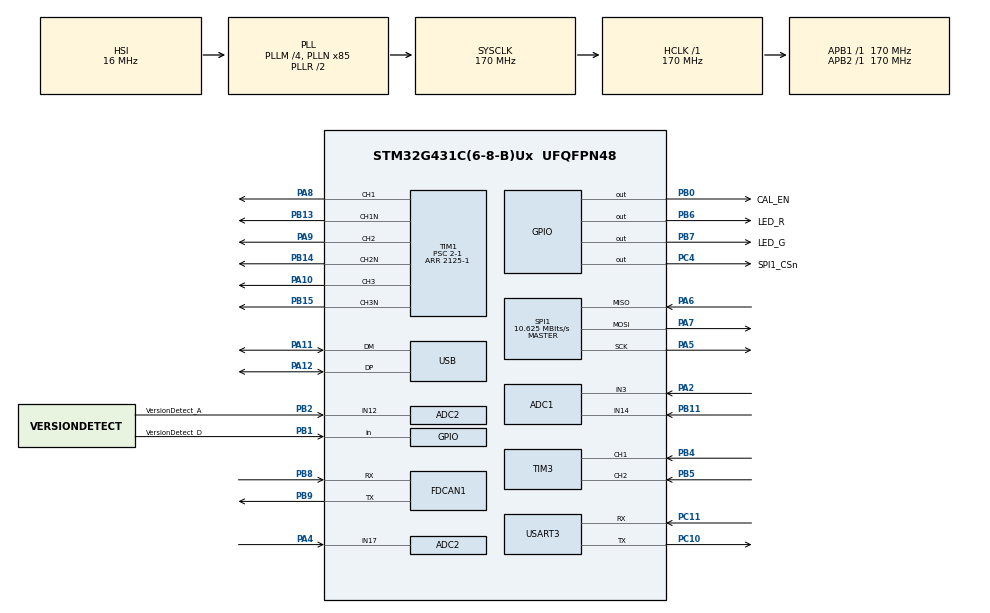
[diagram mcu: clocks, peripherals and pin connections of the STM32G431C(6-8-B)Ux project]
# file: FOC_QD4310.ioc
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ADC1.Channel-2\#ChannelRegularConversion=ADC_CHANNEL_14
ADC1.ClockPrescaler=ADC_CLOCK_SYNC_PCLK_DIV4
ADC1.ContinuousConvMode=DISABLE
ADC1.DMAAccessModeView=DISABLED
ADC1.DMAContinuousRequests=DISABLE
ADC1.EnableAnalogWatchDog1=false
ADC1.EnableInjectedConversion=ENABLE
ADC1.EnableRegularConversion=ENABLE
ADC1.ExternalTrigInjecConv=ADC_EXTERNALTRIGINJEC_T1_TRGO2
ADC1.InjNumberOfConversion=1
ADC1.InjectedChannel-1\#ChannelInjectedConversion=ADC_CHANNEL_3
ADC1.InjectedOffsetNumber-1\#ChannelInjectedConversion=ADC_OFFSET_NONE
ADC1.InjectedRank-1\#ChannelInjectedConversion=1
ADC1.InjectedSamplingTime-1\#ChannelInjectedConversion=ADC_SAMPLETIME_2CYCLES_5
ADC1.Mode=ADC_DUALMODE_REGSIMULT_INJECSIMULT
ADC1.NbrOfConversionFlag=1
ADC1.OffsetNumber-2\#ChannelRegularConversion=ADC_OFFSET_NONE
ADC1.Rank-2\#ChannelRegularConversion=1
ADC1.Rank1_Channel=ADC_CHANNEL_3
ADC1.SamplingTime-2\#ChannelRegularConversion=ADC_SAMPLETIME_2CYCLES_5
ADC1.master=1
ADC2.Channel-3\#ChannelRegularConversion=ADC_CHANNEL_12
ADC2.ClockPrescaler=ADC_CLOCK_SYNC_PCLK_DIV4
ADC2.DMAAccessModeView=DISABLED
ADC2.DMAContinuousRequests=DISABLE
ADC2.EnableInjectedConversion=ENABLE
ADC2.EnableRegularConversion=ENABLE
ADC2.InjNumberOfConversion=1
ADC2.InjectedChannel-2\#ChannelInjectedConversion=ADC_CHANNEL_17
ADC2.InjectedOffsetNumber-2\#ChannelInjectedConversion=ADC_OFFSET_NONE
ADC2.InjectedRank-2\#ChannelInjectedConversion=1
ADC2.InjectedSamplingTime-2\#ChannelInjectedConversion=ADC_SAMPLETIME_2CYCLES_5
ADC2.Mode=ADC_DUALMODE_REGSIMULT_INJECSIMULT
ADC2.NbrOfConversionFlag=1
ADC2.OffsetNumber-3\#ChannelRegularConversion=ADC_OFFSET_NONE
ADC2.Rank-3\#ChannelRegularConversion=1
ADC2.SamplingTime-3\#ChannelRegularConversion=ADC_SAMPLETIME_2CYCLES_5
Dma.Request0=USART3_RX
Dma.Request1=USART3_TX
Dma.USART3_RX.0.Direction=DMA_PERIPH_TO_MEMORY
Dma.USART3_RX.0.EventEnable=DISABLE
Dma.USART3_RX.0.Instance=DMA1_Channel1
Dma.USART3_RX.0.MemDataAlignment=DMA_MDATAALIGN_BYTE
Dma.USART3_RX.0.MemInc=DMA_MINC_ENABLE
Dma.USART3_RX.0.Mode=DMA_NORMAL
Dma.USART3_RX.0.PeriphDataAlignment=DMA_PDATAALIGN_BYTE
Dma.USART3_RX.0.PeriphInc=DMA_PINC_DISABLE
Dma.USART3_RX.0.Polarity=HAL_DMAMUX_REQ_GEN_RISING
Dma.USART3_RX.0.Priority=DMA_PRIORITY_LOW
Dma.USART3_RX.0.RequestNumber=1
Dma.USART3_RX.0.SignalID=NONE
Dma.USART3_RX.0.SyncEnable=DISABLE
Dma.USART3_RX.0.SyncPolarity=HAL_DMAMUX_SYNC_NO_EVENT
Dma.USART3_RX.0.SyncRequestNumber=1
Dma.USART3_RX.0.SyncSignalID=NONE
Dma.USART3_TX.1.Direction=DMA_MEMORY_TO_PERIPH
Dma.USART3_TX.1.EventEnable=DISABLE
Dma.USART3_TX.1.Instance=DMA1_Channel2
Dma.USART3_TX.1.MemDataAlignment=DMA_MDATAALIGN_BYTE
Dma.USART3_TX.1.MemInc=DMA_MINC_ENABLE
Dma.USART3_TX.1.Mode=DMA_NORMAL
Dma.USART3_TX.1.PeriphDataAlignment=DMA_PDATAALIGN_BYTE
Dma.USART3_TX.1.PeriphInc=DMA_PINC_DISABLE
Dma.USART3_TX.1.Polarity=HAL_DMAMUX_REQ_GEN_RISING
Dma.USART3_TX.1.Priority=DMA_PRIORITY_LOW
Dma.USART3_TX.1.RequestNumber=1
Dma.USART3_TX.1.SignalID=NONE
Dma.USART3_TX.1.SyncEnable=DISABLE
Dma.USART3_TX.1.SyncPolarity=HAL_DMAMUX_SYNC_NO_EVENT
Dma.USART3_TX.1.SyncRequestNumber=1
Dma.USART3_TX.1.SyncSignalID=NONE
FDCAN1.AutoRetransmission=ENABLE
FDCAN1.CalculateBaudRateNominal=999999
FDCAN1.CalculateTimeBitNominal=1000
FDCAN1.CalculateTimeQuantumNominal=29.411764705882355
FDCAN1.ClockDivider=FDCAN_CLOCK_DIV1
FDCAN1.DataPrescaler=5
FDCAN1.DataSyncJumpWidth=16
FDCAN1.DataTimeSeg1=17
FDCAN1.DataTimeSeg2=16
FDCAN1.FrameFormat=FDCAN_FRAME_CLASSIC
FDCAN1.Mode=FDCAN_MODE_NORMAL
FDCAN1.NominalPrescaler=5
FDCAN1.NominalSyncJumpWidth=16
FDCAN1.NominalTimeSeg1=17
FDCAN1.NominalTimeSeg2=16
FDCAN1.ProtocolException=ENABLE
FDCAN1.StdFiltersNbr=1
FDCAN1.TransmitPause=DISABLE
FDCAN1.TxFifoQueueMode=FDCAN_TX_FIFO_OPERATION
FREERTOS.Tasks01=DebugTask,24,64,StartDebugTask,As weak,NULL,Dynamic,NULL,NULL;FOCTask,48,128,StartFOCTask,As external,NULL,Dynamic,NULL,NULL;CommunicateTask,32,128,StartCommunicateTask,As external,NULL,Dynamic,NULL,NULL;StartShell,24,128,StartStartShell,As external,NULL,Dynamic,NULL,NULL
FREERTOS.configENABLE_FPU=0
FREERTOS.configMINIMAL_STACK_SIZE=64
FREERTOS.configTOTAL_HEAP_SIZE=6000
FREERTOS.configUSE_NEWLIB_REENTRANT=1
Mcu.Family=STM32G4
Mcu.Name=STM32G431C(6-8-B)Ux
Mcu.Package=UFQFPN48
NVIC.ADC1_2_IRQn=true\:4\:0\:true\:false\:true\:false\:true\:true\:true
NVIC.DMA1_Channel1_IRQn=true\:5\:0\:false\:false\:true\:true\:false\:true\:true
NVIC.DMA1_Channel2_IRQn=true\:5\:0\:false\:false\:true\:true\:false\:true\:true
NVIC.FDCAN1_IT0_IRQn=true\:5\:0\:false\:false\:true\:true\:true\:true\:true
NVIC.FDCAN1_IT1_IRQn=true\:5\:0\:false\:false\:true\:true\:true\:true\:true
NVIC.PriorityGroup=NVIC_PRIORITYGROUP_4
NVIC.TIM6_DAC_IRQn=true\:5\:0\:true\:false\:true\:true\:true\:true\:true
NVIC.USART3_IRQn=true\:5\:0\:true\:false\:true\:true\:true\:true\:true
NVIC.USB_LP_IRQn=true\:5\:0\:false\:false\:true\:true\:false\:true\:true
PA10.Signal=S_TIM1_CH3
PA11.Mode=Device
PA11.Signal=USB_DM
PA12.Mode=Device
PA12.Signal=USB_DP
PA13.Mode=Serial_Wire
PA13.Signal=SYS_JTMS-SWDIO
PA14.Mode=Serial_Wire
PA14.Signal=SYS_JTCK-SWCLK
PA2.Mode=IN3-Single-Ended
PA2.Signal=ADC1_IN3
PA4.Mode=IN17-Single-Ended
PA4.Signal=ADC2_IN17
PA5.Mode=Full_Duplex_Master
PA5.Signal=SPI1_SCK
PA6.Mode=Full_Duplex_Master
PA6.Signal=SPI1_MISO
PA7.Mode=Full_Duplex_Master
PA7.Signal=SPI1_MOSI
PA8.Signal=S_TIM1_CH1
PA9.Signal=S_TIM1_CH2
PB0.GPIO_Label=CAL_EN
PB0.Signal=GPIO_Output
PB1.GPIO_Label=VersionDetect_D
PB1.GPIO_PuPd=GPIO_PULLUP
PB1.Signal=GPIO_Input
PB11.Mode=IN14-Single-Ended
PB11.Signal=ADC1_IN14
PB13.Mode=PWM Generation1 CH1 CH1N
PB13.Signal=TIM1_CH1N
PB14.Mode=PWM Generation2 CH2 CH2N
PB14.Signal=TIM1_CH2N
PB15.Mode=PWM Generation3 CH3 CH3N
PB15.Signal=TIM1_CH3N
PB2.GPIO_Label=VersionDetect_A
PB2.Mode=IN12-Single-Ended
PB2.Signal=ADC2_IN12
PB4.Signal=S_TIM3_CH1
PB5.Signal=S_TIM3_CH2
PB6.GPIO_Label=LED_R
PB6.PinState=GPIO_PIN_SET
PB6.Signal=GPIO_Output
PB7.GPIO_Label=LED_G
PB7.PinState=GPIO_PIN_SET
PB7.Signal=GPIO_Output
PB8-BOOT0.Mode=FDCAN_Activate
PB8-BOOT0.Signal=FDCAN1_RX
PB9.Mode=FDCAN_Activate
PB9.Signal=FDCAN1_TX
PC10.Mode=Asynchronous
PC10.Signal=USART3_TX
PC11.Mode=Asynchronous
PC11.Signal=USART3_RX
PC4.GPIO_Label=SPI1_CSn
PC4.Signal=GPIO_Output
ProjectManager.HeapSize=0x200
ProjectManager.StackSize=0x400
ProjectManager.TargetToolchain=CMake
RCC.ADC12Freq_Value=170000000
RCC.AHBFreq_Value=170000000
RCC.APB1Freq_Value=170000000
RCC.APB1TimFreq_Value=170000000
RCC.APB2Freq_Value=170000000
RCC.APB2TimFreq_Value=170000000
RCC.CK48CLockSelection=RCC_USBCLKSOURCE_HSI48
RCC.CortexFreq_Value=170000000
RCC.EXTERNAL_CLOCK_VALUE=12288000
RCC.HCLKFreq_Value=170000000
RCC.HSE_VALUE=16000000
RCC.HSI48_VALUE=48000000
RCC.HSI_VALUE=16000000
RCC.LSE_VALUE=32768
RCC.PLLM=RCC_PLLM_DIV4
RCC.PLLN=85
RCC.PLLQ=RCC_PLLQ_DIV4
RCC.SYSCLKFreq_VALUE=170000000
RCC.SYSCLKSource=RCC_SYSCLKSOURCE_PLLCLK
RCC.USBFreq_Value=48000000
RCC.VCOOutputFreq_Value=340000000
SH.S_TIM1_CH1.0=TIM1_CH1,PWM Generation1 CH1 CH1N
SH.S_TIM1_CH2.0=TIM1_CH2,PWM Generation2 CH2 CH2N
SH.S_TIM1_CH3.0=TIM1_CH3,PWM Generation3 CH3 CH3N
SH.S_TIM3_CH1.0=TIM3_CH1,Input_Capture1_from_TI1
SH.S_TIM3_CH2.0=TIM3_CH2,Input_Capture2_from_TI2
SPI1.BaudRatePrescaler=SPI_BAUDRATEPRESCALER_16
SPI1.CLKPhase=SPI_PHASE_2EDGE
SPI1.CLKPolarity=SPI_POLARITY_HIGH
SPI1.CalculateBaudRate=10.625 MBits/s
SPI1.DataSize=SPI_DATASIZE_8BIT
SPI1.Direction=SPI_DIRECTION_2LINES
SPI1.Mode=SPI_MODE_MASTER
SPI1.VirtualType=VM_MASTER
TIM1.Channel-PWM\ Generation1\ CH1\ CH1N=TIM_CHANNEL_1
TIM1.Channel-PWM\ Generation2\ CH2\ CH2N=TIM_CHANNEL_2
TIM1.Channel-PWM\ Generation3\ CH3\ CH3N=TIM_CHANNEL_3
TIM1.Channel-PWM\ Generation4\ No\ Output=TIM_CHANNEL_4
TIM1.CounterMode=TIM_COUNTERMODE_CENTERALIGNED1
TIM1.OC1Preload_PWM=ENABLE
TIM1.OC2Preload_PWM=ENABLE
TIM1.OC3Preload_PWM=ENABLE
TIM1.PeriodNoDither=2125-1
TIM1.Prescaler=2-1
TIM1.PulseNoDither_4=5
TIM1.TIM_MasterOutputTrigger=TIM_TRGO_UPDATE
TIM1.TIM_MasterOutputTrigger2=TIM_TRGO2_OC4REF
TIM3.Channel-Input_Capture1_from_TI1=TIM_CHANNEL_1
TIM3.Channel-Input_Capture2_from_TI2=TIM_CHANNEL_2
TIM6.PeriodNoDither=200-1
TIM6.Prescaler=170-1
TIM6.TIM_MasterOutputTrigger=TIM_TRGO_RESET
USART3.FIFOMode=FIFOMODE_ENABLE
USART3.RXFIFOThreshold=RXFIFO_THRESHOLD_FULL
USART3.TXFIFOThreshold=TXFIFO_THRESHOLD_EMPTY
USART3.VirtualMode-Asynchronous=VM_ASYNC
USB_DEVICE.APP_RX_DATA_SIZE=256
USB_DEVICE.APP_TX_DATA_SIZE=64
USB_DEVICE.CLASS_NAME_FS=CDC
USB_DEVICE.PID_CDC_FS=22337
USB_DEVICE.PRODUCT_STRING_CDC_FS=QDrive ComPort
USB_DEVICE.VirtualMode=Cdc
USB_DEVICE.VirtualModeFS=Cdc_FS
VP_FREERTOS_VS_CMSIS_V2.Mode=CMSIS_V2
VP_SYS_VS_DBSignals.Mode=DisableDeadBatterySignals
VP_TIM1_VS_ClockSourceINT.Mode=Internal
VP_TIM1_VS_no_output4.Mode=PWM Generation4 No Output
VP_TIM3_VS_ClockSourceINT.Mode=Internal
VP_TIM6_VS_ClockSourceINT.Mode=Enable_Timer
VP_USB_DEVICE_VS_USB_DEVICE_CDC_FS.Mode=CDC_FS
board=custom

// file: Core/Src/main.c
/* USER CODE BEGIN Header */
/**
  ******************************************************************************
  * @file           : main.c
  * @brief          : Main program body
  ******************************************************************************
  * @attention
  *
  * Copyright (c) 2024 STMicroelectronics.
  * All rights reserved.
  *
  * This software is licensed under terms that can be found in the LICENSE file
  * in the root directory of this software component.
  * If no LICENSE file comes with this software, it is provided AS-IS.
  *
  ******************************************************************************
  */
/* USER CODE END Header */
#include "main.h"
#include "cmsis_os.h"
#include "adc.h"
#include "dma.h"
#include "fdcan.h"
#include "spi.h"
#include "tim.h"
#include "usart.h"
#include "usb_device.h"
#include "gpio.h"

/* USER CODE BEGIN Includes */
#include "sys_public.h"
/* USER CODE END Includes */

void SystemClock_Config(void);
void MX_FREERTOS_Init(void);

int main(void)
{

  /* MCU Configuration--------------------------------------------------------*/

  /* Reset of all peripherals, Initializes the Flash interface and the Systick. */
  HAL_Init();

  /* Configure the system clock */
  SystemClock_Config();

  /* Initialize all configured peripherals */
  MX_GPIO_Init();
  MX_DMA_Init();
  MX_ADC1_Init();
  MX_TIM6_Init();
  MX_ADC2_Init();
  MX_FDCAN1_Init();
  MX_SPI1_Init();
  MX_TIM1_Init();
  MX_TIM3_Init();
  MX_USART3_UART_Init();
  /* USER CODE BEGIN 2 */
  version_detect(); // 硬件版本检测
  /* USER CODE END 2 */

  /* Init scheduler */
  osKernelInitialize();

  /* Call init function for freertos objects (in cmsis_os2.c) */
  MX_FREERTOS_Init();

  /* Start scheduler */
  osKernelStart();

  /* We should never get here as control is now taken by the scheduler */

  /* Infinite loop */
    while (1) {

    }
}

void SystemClock_Config(void)
{
  RCC_OscInitTypeDef RCC_OscInitStruct = {0};
  RCC_ClkInitTypeDef RCC_ClkInitStruct = {0};

  /** Configure the main internal regulator output voltage
  */
  HAL_PWREx_ControlVoltageScaling(PWR_REGULATOR_VOLTAGE_SCALE1_BOOST);

  /** Initializes the RCC Oscillators according to the specified parameters
  * in the RCC_OscInitTypeDef structure.
  */
  RCC_OscInitStruct.OscillatorType = RCC_OSCILLATORTYPE_HSI|RCC_OSCILLATORTYPE_HSI48;
  RCC_OscInitStruct.HSIState = RCC_HSI_ON;
  RCC_OscInitStruct.HSICalibrationValue = RCC_HSICALIBRATION_DEFAULT;
  RCC_OscInitStruct.HSI48State = RCC_HSI48_ON;
  RCC_OscInitStruct.PLL.PLLState = RCC_PLL_ON;
  RCC_OscInitStruct.PLL.PLLSource = RCC_PLLSOURCE_HSI;
  RCC_OscInitStruct.PLL.PLLM = RCC_PLLM_DIV4;
  RCC_OscInitStruct.PLL.PLLN = 85;
  RCC_OscInitStruct.PLL.PLLP = RCC_PLLP_DIV2;
  RCC_OscInitStruct.PLL.PLLQ = RCC_PLLQ_DIV4;
  RCC_OscInitStruct.PLL.PLLR = RCC_PLLR_DIV2;
  if (HAL_RCC_OscConfig(&RCC_OscInitStruct) != HAL_OK)
  {
    Error_Handler();
  }

  /** Initializes the CPU, AHB and APB buses clocks
  */
  RCC_ClkInitStruct.ClockType = RCC_CLOCKTYPE_HCLK|RCC_CLOCKTYPE_SYSCLK
                              |RCC_CLOCKTYPE_PCLK1|RCC_CLOCKTYPE_PCLK2;
  RCC_ClkInitStruct.SYSCLKSource = RCC_SYSCLKSOURCE_PLLCLK;
  RCC_ClkInitStruct.AHBCLKDivider = RCC_SYSCLK_DIV1;
  RCC_ClkInitStruct.APB1CLKDivider = RCC_HCLK_DIV1;
  RCC_ClkInitStruct.APB2CLKDivider = RCC_HCLK_DIV1;

  if (HAL_RCC_ClockConfig(&RCC_ClkInitStruct, FLASH_LATENCY_4) != HAL_OK)
  {
    Error_Handler();
  }
}

void Error_Handler(void)
{
    __disable_irq();
    while (1) {
    }
}

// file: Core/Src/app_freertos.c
/* USER CODE BEGIN Header */
/**
  ******************************************************************************
  * File Name          : app_freertos.c
  * Description        : Code for freertos applications
  ******************************************************************************
  * @attention
  *
  * Copyright (c) 2024 STMicroelectronics.
  * All rights reserved.
  *
  * This software is licensed under terms that can be found in the LICENSE file
  * in the root directory of this software component.
  * If no LICENSE file comes with this software, it is provided AS-IS.
  *
  ******************************************************************************
  */
/* USER CODE END Header */

#include "FreeRTOS.h"
#include "task.h"
#include "main.h"
#include "cmsis_os.h"

#include "usb_device.h"

/* USER CODE BEGIN Includes */
#include "task_public.h"
/* USER CODE END Includes */

/* Definitions for DebugTask */
osThreadId_t DebugTaskHandle;
const osThreadAttr_t DebugTask_attributes = {
  .name = "DebugTask",
  .priority = (osPriority_t) osPriorityNormal,
  .stack_size = 64 * 4
};
/* Definitions for FOCTask */
osThreadId_t FOCTaskHandle;
const osThreadAttr_t FOCTask_attributes = {
  .name = "FOCTask",
  .priority = (osPriority_t) osPriorityRealtime,
  .stack_size = 128 * 4
};
/* Definitions for CommunicateTask */
osThreadId_t CommunicateTaskHandle;
const osThreadAttr_t CommunicateTask_attributes = {
  .name = "CommunicateTask",
  .priority = (osPriority_t) osPriorityAboveNormal,
  .stack_size = 128 * 4
};
/* Definitions for StartShell */
osThreadId_t StartShellHandle;
const osThreadAttr_t StartShell_attributes = {
  .name = "StartShell",
  .priority = (osPriority_t) osPriorityNormal,
  .stack_size = 128 * 4
};

void StartDebugTask(void *argument);
extern void StartFOCTask(void *argument);
extern void StartCommunicateTask(void *argument);
extern void StartStartShell(void *argument);

void MX_FREERTOS_Init(void); /* (MISRA C 2004 rule 8.1) */

void MX_FREERTOS_Init(void) {

  /* Create the thread(s) */
  /* creation of DebugTask */
  DebugTaskHandle = osThreadNew(StartDebugTask, NULL, &DebugTask_attributes);

  /* creation of FOCTask */
  FOCTaskHandle = osThreadNew(StartFOCTask, NULL, &FOCTask_attributes);

  /* creation of CommunicateTask */
  CommunicateTaskHandle = osThreadNew(StartCommunicateTask, NULL, &CommunicateTask_attributes);

  /* creation of StartShell */
  StartShellHandle = osThreadNew(StartStartShell, NULL, &StartShell_attributes);

}

__weak void StartDebugTask(void *argument)
{
  /* init code for USB_Device */
  MX_USB_Device_Init();
  for(;;)
  {
    osDelay(1);
  }
}
